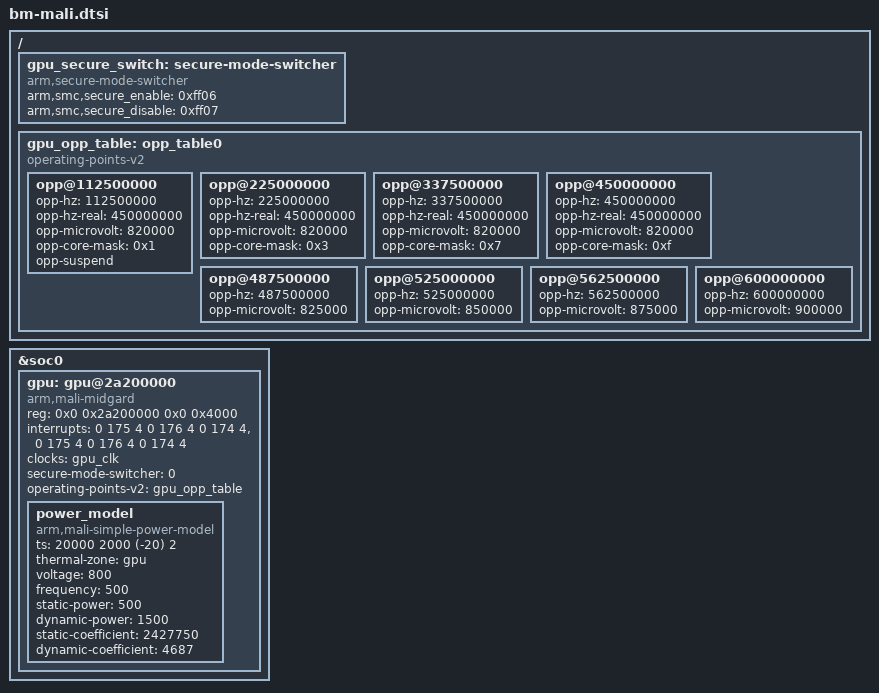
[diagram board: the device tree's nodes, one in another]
// SPDX-License-Identifier: GPL-2.0
/ {
	gpu_secure_switch: secure-mode-switcher {
		compatible = "arm,secure-mode-switcher";
		arm,smc,secure_enable = <0xff06>;
		arm,smc,secure_disable = <0xff07>;
	};

	gpu_opp_table: opp_table0 {
		compatible = "operating-points-v2", "operating-points-v2-mali";

		opp@112500000 {
			opp-hz = /bits/ 64 <112500000>;
			opp-hz-real = /bits/ 64 <450000000>;
			opp-microvolt = <820000>;
			opp-core-mask = /bits/ 64 <0x1>;
			opp-suspend;
		};
		opp@225000000 {
			opp-hz = /bits/ 64 <225000000>;
			opp-hz-real = /bits/ 64 <450000000>;
			opp-microvolt = <820000>;
			opp-core-mask = /bits/ 64 <0x3>;
		};
		opp@337500000 {
			opp-hz = /bits/ 64 <337500000>;
			opp-hz-real = /bits/ 64 <450000000>;
			opp-microvolt = <820000>;
			opp-core-mask = /bits/ 64 <0x7>;
		};
		opp@450000000 {
			opp-hz = /bits/ 64 <450000000>;
			opp-hz-real = /bits/ 64 <450000000>;
			opp-microvolt = <820000>;
			opp-core-mask = /bits/ 64 <0xf>;
		};
		opp@487500000 {
			opp-hz = /bits/ 64 <487500000>;
			opp-microvolt = <825000>;
		};
		opp@525000000 {
			opp-hz = /bits/ 64 <525000000>;
			opp-microvolt = <850000>;
		};
		opp@562500000 {
			opp-hz = /bits/ 64 <562500000>;
			opp-microvolt = <875000>;
		};
		opp@600000000 {
			opp-hz = /bits/ 64 <600000000>;
			opp-microvolt = <900000>;
		};
	};
};

&soc0 {
	gpu: gpu@2a200000 {
		compatible = "arm,mali-midgard", "arm,mali-t624";
		#cooling-cells = <2>; /* min followed by max */
		reg = <0x0 0x2a200000 0x0 0x4000>;
		interrupts = <0 175 4 0 176 4 0 174 4>,
				<0 175 4 0 176 4 0 174 4>;
//        interrupt-names = "JOB", "MMU", "GPU";
		interrupt-names = "job", "mmu", "gpu",
					"JOB", "MMU", "GPU";
		clocks = <&gpu_clk>;
		clock-names = "gpuclk";
//		secure-mode-switcher = <&gpu_secure_switch>;
		secure-mode-switcher = <0>;
		operating-points-v2 = <&gpu_opp_table>;
		power_model {
			compatible = "arm,mali-simple-power-model";
			ts = <20000 2000 (-20) 2>;
			thermal-zone = "gpu";
			/* Old Power Model */
			voltage = <800>;
			frequency = <500>;
			static-power = <500>;
			dynamic-power = <1500>;
			/* New Power Model */
			static-coefficient = <2427750>;
			dynamic-coefficient = <4687>;
		};
	};
};
